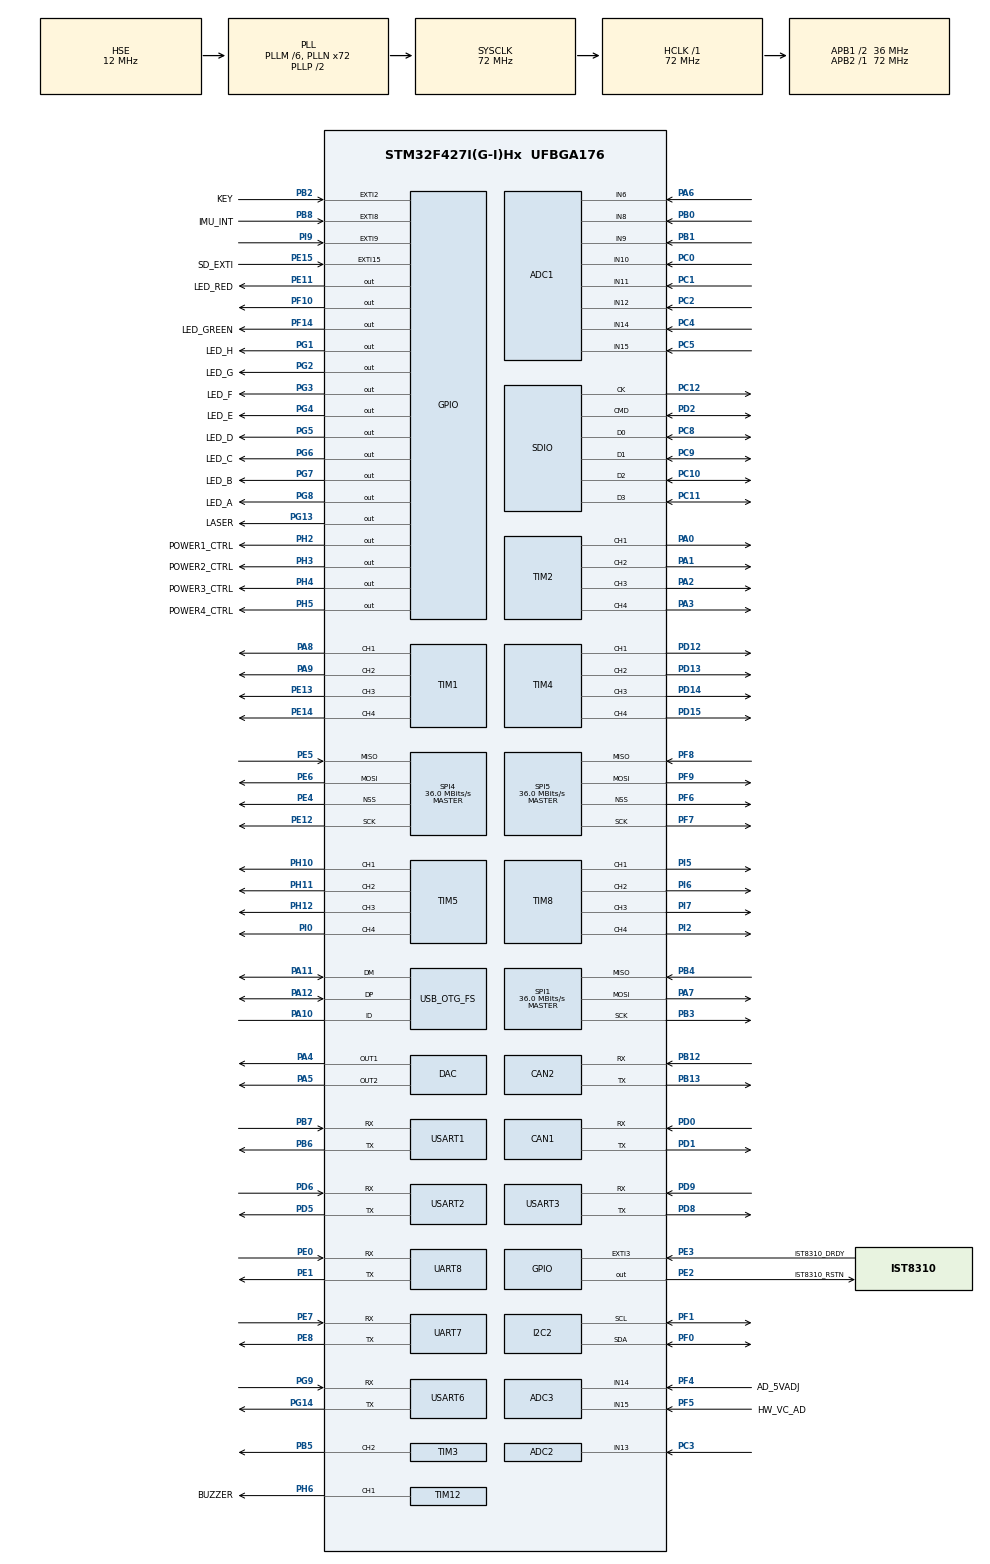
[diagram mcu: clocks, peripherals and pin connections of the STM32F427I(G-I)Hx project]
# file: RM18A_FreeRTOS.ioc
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ADC1.Channel-0\#ChannelRegularConversion=ADC_CHANNEL_6
ADC1.NbrOfConversionFlag=1
ADC1.Rank-0\#ChannelRegularConversion=1
ADC1.SamplingTime-0\#ChannelRegularConversion=ADC_SAMPLETIME_3CYCLES
ADC1.master=1
ADC2.Channel-0\#ChannelRegularConversion=ADC_CHANNEL_13
ADC2.NbrOfConversionFlag=1
ADC2.Rank-0\#ChannelRegularConversion=1
ADC2.SamplingTime-0\#ChannelRegularConversion=ADC_SAMPLETIME_3CYCLES
ADC3.Channel-0\#ChannelRegularConversion=ADC_CHANNEL_14
ADC3.NbrOfConversionFlag=1
ADC3.Rank-0\#ChannelRegularConversion=1
ADC3.SamplingTime-0\#ChannelRegularConversion=ADC_SAMPLETIME_3CYCLES
CAN1.CalculateTimeQuantum=444.44444444444446
CAN2.CalculateTimeQuantum=444.44444444444446
FREERTOS.Tasks01=defaultTask,0,128,StartDefaultTask,Default,NULL
Mcu.Family=STM32F4
Mcu.Name=STM32F427I(G-I)Hx
Mcu.Package=UFBGA176
NVIC.PriorityGroup=NVIC_PRIORITYGROUP_4
NVIC.TIM8_TRG_COM_TIM14_IRQn=true\:5\:0\:false\:false\:true\:true\:false\:true
NVIC.TimeBase=TIM8_TRG_COM_TIM14_IRQn
NVIC.TimeBaseIP=TIM14
PA0/WKUP.Signal=S_TIM2_CH1_ETR
PA1.Signal=S_TIM2_CH2
PA10.Mode=OTG/Dual_Role_Device
PA10.Signal=USB_OTG_FS_ID
PA11.Mode=OTG/Dual_Role_Device
PA11.Signal=USB_OTG_FS_DM
PA12.Mode=OTG/Dual_Role_Device
PA12.Signal=USB_OTG_FS_DP
PA13.Mode=Serial_Wire
PA13.Signal=SYS_JTMS-SWDIO
PA14.Mode=Serial_Wire
PA14.Signal=SYS_JTCK-SWCLK
PA2.Signal=S_TIM2_CH3
PA3.Signal=S_TIM2_CH4
PA4.Signal=COMP_DAC1_group
PA5.Signal=COMP_DAC2_group
PA6.Signal=ADCx_IN6
PA7.Mode=Full_Duplex_Master
PA7.Signal=SPI1_MOSI
PA8.Signal=S_TIM1_CH1
PA9.Signal=S_TIM1_CH2
PB0.Signal=ADCx_IN8
PB1.Signal=ADCx_IN9
PB12.Mode=Slave
PB12.Signal=CAN2_RX
PB13.Mode=Slave
PB13.Signal=CAN2_TX
PB2/BOOT1.GPIO_Label=KEY
PB2/BOOT1.Signal=GPXTI2
PB3.Mode=Full_Duplex_Master
PB3.Signal=SPI1_SCK
PB4.Mode=Full_Duplex_Master
PB4.Signal=SPI1_MISO
PB5.Signal=S_TIM3_CH2
PB6.Mode=Asynchronous
PB6.Signal=USART1_TX
PB7.Mode=Asynchronous
PB7.Signal=USART1_RX
PB8.GPIO_Label=IMU_INT
PB8.Signal=GPXTI8
PC0.Signal=ADCx_IN10
PC1.Signal=ADCx_IN11
PC10.Mode=SD_4_bits_Wide_bus
PC10.Signal=SDIO_D2
PC11.Mode=SD_4_bits_Wide_bus
PC11.Signal=SDIO_D3
PC12.Mode=SD_4_bits_Wide_bus
PC12.Signal=SDIO_CK
PC2.Signal=ADCx_IN12
PC3.Signal=ADCx_IN13
PC4.Signal=ADCx_IN14
PC5.Signal=ADCx_IN15
PC8.Mode=SD_4_bits_Wide_bus
PC8.Signal=SDIO_D0
PC9.Mode=SD_4_bits_Wide_bus
PC9.Signal=SDIO_D1
PD0.Mode=Master
PD0.Signal=CAN1_RX
PD1.Mode=Master
PD1.Signal=CAN1_TX
PD12.Signal=S_TIM4_CH1
PD13.Signal=S_TIM4_CH2
PD14.Signal=S_TIM4_CH3
PD15.Signal=S_TIM4_CH4
PD2.Mode=SD_4_bits_Wide_bus
PD2.Signal=SDIO_CMD
PD5.Mode=Asynchronous
PD5.Signal=USART2_TX
PD6.Mode=Asynchronous
PD6.Signal=USART2_RX
PD8.Mode=Asynchronous
PD8.Signal=USART3_TX
PD9.Mode=Asynchronous
PD9.Signal=USART3_RX
PE0.Mode=Asynchronous
PE0.Signal=UART8_RX
PE1.Mode=Asynchronous
PE1.Signal=UART8_TX
PE11.GPIO_Label=LED_RED
PE11.Signal=GPIO_Output
PE12.Mode=Full_Duplex_Master
PE12.Signal=SPI4_SCK
PE13.Signal=S_TIM1_CH3
PE14.Signal=S_TIM1_CH4
PE15.GPIO_Label=SD_EXTI
PE15.Signal=GPXTI15
PE2.GPIO_Label=IST8310_RSTN
PE2.Signal=GPIO_Output
PE3.GPIO_Label=IST8310_DRDY
PE3.Signal=GPXTI3
PE4.Mode=NSS_Signal_Hard_Output
PE4.Signal=SPI4_NSS
PE5.Mode=Full_Duplex_Master
PE5.Signal=SPI4_MISO
PE6.Mode=Full_Duplex_Master
PE6.Signal=SPI4_MOSI
PE7.Mode=Asynchronous
PE7.Signal=UART7_RX
PE8.Mode=Asynchronous
PE8.Signal=UART7_TX
PF0.Mode=I2C
PF0.Signal=I2C2_SDA
PF1.Mode=I2C
PF1.Signal=I2C2_SCL
PF10.Signal=GPIO_Output
PF14.GPIO_Label=LED_GREEN
PF14.Signal=GPIO_Output
PF4.GPIO_Label=AD_5VADJ
PF4.Mode=IN14
PF4.Signal=ADC3_IN14
PF5.GPIO_Label=HW_VC_AD
PF5.Mode=IN15
PF5.Signal=ADC3_IN15
PF6.Mode=NSS_Signal_Hard_Output
PF6.Signal=SPI5_NSS
PF7.Mode=Full_Duplex_Master
PF7.Signal=SPI5_SCK
PF8.Mode=Full_Duplex_Master
PF8.Signal=SPI5_MISO
PF9.Mode=Full_Duplex_Master
PF9.Signal=SPI5_MOSI
PG1.GPIO_Label=LED_H
PG1.Signal=GPIO_Output
PG13.GPIO_Label=LASER
PG13.Signal=GPIO_Output
PG14.Mode=Asynchronous
PG14.Signal=USART6_TX
PG2.GPIO_Label=LED_G
PG2.Signal=GPIO_Output
PG3.GPIO_Label=LED_F
PG3.Signal=GPIO_Output
PG4.GPIO_Label=LED_E
PG4.Signal=GPIO_Output
PG5.GPIO_Label=LED_D
PG5.Signal=GPIO_Output
PG6.GPIO_Label=LED_C
PG6.Signal=GPIO_Output
PG7.GPIO_Label=LED_B
PG7.Signal=GPIO_Output
PG8.GPIO_Label=LED_A
PG8.Signal=GPIO_Output
PG9.Mode=Asynchronous
PG9.Signal=USART6_RX
PH0/OSC_IN.Mode=HSE-External-Oscillator
PH0/OSC_IN.Signal=RCC_OSC_IN
PH1/OSC_OUT.Mode=HSE-External-Oscillator
PH1/OSC_OUT.Signal=RCC_OSC_OUT
PH10.Signal=S_TIM5_CH1
PH11.Signal=S_TIM5_CH2
PH12.Signal=S_TIM5_CH3
PH2.GPIO_Label=POWER1_CTRL
PH2.Signal=GPIO_Output
PH3.GPIO_Label=POWER2_CTRL
PH3.Signal=GPIO_Output
PH4.GPIO_Label=POWER3_CTRL
PH4.Signal=GPIO_Output
PH5.GPIO_Label=POWER4_CTRL
PH5.Signal=GPIO_Output
PH6.GPIO_Label=BUZZER
PH6.Signal=S_TIM12_CH1
PI0.Signal=S_TIM5_CH4
PI2.Signal=S_TIM8_CH4
PI5.Signal=S_TIM8_CH1
PI6.Signal=S_TIM8_CH2
PI7.Signal=S_TIM8_CH3
PI9.Signal=GPXTI9
ProjectManager.HeapSize=0x200
ProjectManager.StackSize=0x400
ProjectManager.TargetToolchain=Makefile
RCC.48MHZClocksFreq_Value=48000000
RCC.AHBFreq_Value=72000000
RCC.APB1CLKDivider=RCC_HCLK_DIV2
RCC.APB1Freq_Value=36000000
RCC.APB1TimFreq_Value=72000000
RCC.APB2Freq_Value=72000000
RCC.APB2TimFreq_Value=72000000
RCC.CortexFreq_Value=72000000
RCC.HCLKFreq_Value=72000000
RCC.HSE_VALUE=12000000
RCC.HSI_VALUE=16000000
RCC.LSE_VALUE=32768
RCC.PLLM=6
RCC.PLLN=72
RCC.PLLQ=3
RCC.SYSCLKFreq_VALUE=72000000
RCC.SYSCLKSource=RCC_SYSCLKSOURCE_PLLCLK
RCC.VCOOutputFreq_Value=144000000
SH.ADCx_IN10.0=ADC1_IN10,IN10
SH.ADCx_IN11.0=ADC1_IN11,IN11
SH.ADCx_IN12.0=ADC1_IN12,IN12
SH.ADCx_IN13.0=ADC2_IN13,IN13
SH.ADCx_IN13.1=ADC1_IN13,IN13
SH.ADCx_IN14.0=ADC1_IN14,IN14
SH.ADCx_IN15.0=ADC1_IN15,IN15
SH.ADCx_IN6.0=ADC1_IN6,IN6
SH.ADCx_IN8.0=ADC1_IN8,IN8
SH.ADCx_IN9.0=ADC1_IN9,IN9
SH.COMP_DAC1_group.0=DAC_OUT1,DAC_OUT1
SH.COMP_DAC2_group.0=DAC_OUT2,DAC_OUT2
SH.S_TIM12_CH1.0=TIM12_CH1,Output Compare1 CH1
SH.S_TIM1_CH1.0=TIM1_CH1,PWM Generation1 CH1
SH.S_TIM1_CH2.0=TIM1_CH2,Output Compare2 CH2
SH.S_TIM1_CH3.0=TIM1_CH3,PWM Generation3 CH3
SH.S_TIM1_CH4.0=TIM1_CH4,PWM Generation4 CH4
SH.S_TIM2_CH1_ETR.0=TIM2_CH1,PWM Generation1 CH1
SH.S_TIM2_CH2.0=TIM2_CH2,PWM Generation2 CH2
SH.S_TIM2_CH3.0=TIM2_CH3,PWM Generation3 CH3
SH.S_TIM2_CH4.0=TIM2_CH4,PWM Generation4 CH4
SH.S_TIM3_CH2.0=TIM3_CH2,PWM Generation2 CH2
SH.S_TIM4_CH1.0=TIM4_CH1,PWM Generation1 CH1
SH.S_TIM4_CH2.0=TIM4_CH2,PWM Generation2 CH2
SH.S_TIM4_CH3.0=TIM4_CH3,PWM Generation3 CH3
SH.S_TIM4_CH4.0=TIM4_CH4,PWM Generation4 CH4
SH.S_TIM5_CH1.0=TIM5_CH1,PWM Generation1 CH1
SH.S_TIM5_CH2.0=TIM5_CH2,PWM Generation2 CH2
SH.S_TIM5_CH3.0=TIM5_CH3,PWM Generation3 CH3
SH.S_TIM5_CH4.0=TIM5_CH4,PWM Generation4 CH4
SH.S_TIM8_CH1.0=TIM8_CH1,PWM Generation1 CH1
SH.S_TIM8_CH2.0=TIM8_CH2,PWM Generation2 CH2
SH.S_TIM8_CH3.0=TIM8_CH3,PWM Generation3 CH3
SH.S_TIM8_CH4.0=TIM8_CH4,PWM Generation4 CH4
SPI1.CalculateBaudRate=36.0 MBits/s
SPI1.Direction=SPI_DIRECTION_2LINES
SPI1.Mode=SPI_MODE_MASTER
SPI1.VirtualType=VM_MASTER
SPI4.CalculateBaudRate=36.0 MBits/s
SPI4.Direction=SPI_DIRECTION_2LINES
SPI4.Mode=SPI_MODE_MASTER
SPI4.VirtualNSS=VM_NSSHARD
SPI4.VirtualType=VM_MASTER
SPI5.CalculateBaudRate=36.0 MBits/s
SPI5.Direction=SPI_DIRECTION_2LINES
SPI5.Mode=SPI_MODE_MASTER
SPI5.VirtualNSS=VM_NSSHARD
SPI5.VirtualType=VM_MASTER
TIM1.Channel-Output\ Compare2\ CH2=TIM_CHANNEL_2
TIM1.Channel-PWM\ Generation1\ CH1=TIM_CHANNEL_1
TIM1.Channel-PWM\ Generation3\ CH3=TIM_CHANNEL_3
TIM1.Channel-PWM\ Generation4\ CH4=TIM_CHANNEL_4
TIM12.Channel-Output\ Compare1\ CH1=TIM_CHANNEL_1
TIM2.Channel-PWM\ Generation1\ CH1=TIM_CHANNEL_1
TIM2.Channel-PWM\ Generation2\ CH2=TIM_CHANNEL_2
TIM2.Channel-PWM\ Generation3\ CH3=TIM_CHANNEL_3
TIM2.Channel-PWM\ Generation4\ CH4=TIM_CHANNEL_4
TIM3.Channel-PWM\ Generation2\ CH2=TIM_CHANNEL_2
TIM4.Channel-PWM\ Generation1\ CH1=TIM_CHANNEL_1
TIM4.Channel-PWM\ Generation2\ CH2=TIM_CHANNEL_2
TIM4.Channel-PWM\ Generation3\ CH3=TIM_CHANNEL_3
TIM4.Channel-PWM\ Generation4\ CH4=TIM_CHANNEL_4
TIM5.Channel-PWM\ Generation1\ CH1=TIM_CHANNEL_1
TIM5.Channel-PWM\ Generation2\ CH2=TIM_CHANNEL_2
TIM5.Channel-PWM\ Generation3\ CH3=TIM_CHANNEL_3
TIM5.Channel-PWM\ Generation4\ CH4=TIM_CHANNEL_4
TIM8.Channel-PWM\ Generation1\ CH1=TIM_CHANNEL_1
TIM8.Channel-PWM\ Generation2\ CH2=TIM_CHANNEL_2
TIM8.Channel-PWM\ Generation3\ CH3=TIM_CHANNEL_3
TIM8.Channel-PWM\ Generation4\ CH4=TIM_CHANNEL_4
UART7.VirtualMode=Asynchronous
UART8.VirtualMode=Asynchronous
USART1.VirtualMode=VM_ASYNC
USART2.VirtualMode=VM_ASYNC
USART3.VirtualMode=VM_ASYNC
USART6.VirtualMode=VM_ASYNC
VP_CRC_VS_CRC.Mode=CRC_Activate
VP_FREERTOS_VS_CMSIS_V1.Mode=CMSIS_V1
VP_SYS_VS_tim14.Mode=TIM14
board=custom

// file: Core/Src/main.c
/* USER CODE BEGIN Header */
/**
  ******************************************************************************
  * @file           : main.c
  * @brief          : Main program body
  ******************************************************************************
  * @attention
  *
  * <h2><center>&copy; Copyright (c) 2019 STMicroelectronics.
  * All rights reserved.</center></h2>
  *
  * This software component is licensed by ST under Ultimate Liberty license
  * SLA0044, the "License"; You may not use this file except in compliance with
  * the License. You may obtain a copy of the License at:
  *                             www.st.com/SLA0044
  *
  ******************************************************************************
  */
/* USER CODE END Header */

#include "main.h"
#include "cmsis_os.h"

ADC_HandleTypeDef hadc1;
ADC_HandleTypeDef hadc2;
ADC_HandleTypeDef hadc3;

CAN_HandleTypeDef hcan1;
CAN_HandleTypeDef hcan2;

CRC_HandleTypeDef hcrc;

DAC_HandleTypeDef hdac;

I2C_HandleTypeDef hi2c2;

SD_HandleTypeDef hsd;

SPI_HandleTypeDef hspi1;
SPI_HandleTypeDef hspi4;
SPI_HandleTypeDef hspi5;

TIM_HandleTypeDef htim1;
TIM_HandleTypeDef htim2;
TIM_HandleTypeDef htim3;
TIM_HandleTypeDef htim4;
TIM_HandleTypeDef htim5;
TIM_HandleTypeDef htim8;
TIM_HandleTypeDef htim12;

UART_HandleTypeDef huart7;
UART_HandleTypeDef huart8;
UART_HandleTypeDef huart1;
UART_HandleTypeDef huart2;
UART_HandleTypeDef huart3;
UART_HandleTypeDef huart6;

osThreadId defaultTaskHandle;

void SystemClock_Config(void);
static void MX_GPIO_Init(void);
static void MX_CRC_Init(void);
static void MX_USB_OTG_FS_USB_Init(void);
static void MX_SDIO_SD_Init(void);
static void MX_CAN1_Init(void);
static void MX_CAN2_Init(void);
static void MX_I2C2_Init(void);
static void MX_ADC1_Init(void);
static void MX_ADC2_Init(void);
static void MX_DAC_Init(void);
static void MX_SPI1_Init(void);
static void MX_TIM1_Init(void);
static void MX_TIM2_Init(void);
static void MX_TIM3_Init(void);
static void MX_TIM4_Init(void);
static void MX_TIM5_Init(void);
static void MX_TIM12_Init(void);
static void MX_UART8_Init(void);
static void MX_USART1_UART_Init(void);
static void MX_USART2_UART_Init(void);
static void MX_USART3_UART_Init(void);
static void MX_USART6_UART_Init(void);
static void MX_ADC3_Init(void);
static void MX_SPI4_Init(void);
static void MX_SPI5_Init(void);
static void MX_TIM8_Init(void);
static void MX_UART7_Init(void);
void StartDefaultTask(void const *argument);

int main(void)
{

  /* MCU Configuration--------------------------------------------------------*/

  /* Reset of all peripherals, Initializes the Flash interface and the Systick. */
  HAL_Init();

  /* Configure the system clock */
  SystemClock_Config();

  /* Initialize all configured peripherals */
  MX_GPIO_Init();
  MX_CRC_Init();
  MX_USB_OTG_FS_USB_Init();
  MX_SDIO_SD_Init();
  MX_CAN1_Init();
  MX_CAN2_Init();
  MX_I2C2_Init();
  MX_ADC1_Init();
  MX_ADC2_Init();
  MX_DAC_Init();
  MX_SPI1_Init();
  MX_TIM1_Init();
  MX_TIM2_Init();
  MX_TIM3_Init();
  MX_TIM4_Init();
  MX_TIM5_Init();
  MX_TIM12_Init();
  MX_UART8_Init();
  MX_USART1_UART_Init();
  MX_USART2_UART_Init();
  MX_USART3_UART_Init();
  MX_USART6_UART_Init();
  MX_ADC3_Init();
  MX_SPI4_Init();
  MX_SPI5_Init();
  MX_TIM8_Init();
  MX_UART7_Init();

  /* Create the thread(s) */
  /* definition and creation of defaultTask */
  osThreadDef(defaultTask, StartDefaultTask, osPriorityNormal, 0, 128);
  defaultTaskHandle = osThreadCreate(osThread(defaultTask), NULL);

  /* Start scheduler */
  osKernelStart();

  /* We should never get here as control is now taken by the scheduler */

  /* Infinite loop */
  while (1)
  {

  }
}

void SystemClock_Config(void)
{
  RCC_OscInitTypeDef RCC_OscInitStruct = {0};
  RCC_ClkInitTypeDef RCC_ClkInitStruct = {0};

  /** Configure the main internal regulator output voltage
  */
  __HAL_RCC_PWR_CLK_ENABLE();
  __HAL_PWR_VOLTAGESCALING_CONFIG(PWR_REGULATOR_VOLTAGE_SCALE3);
  /** Initializes the CPU, AHB and APB busses clocks
  */
  RCC_OscInitStruct.OscillatorType = RCC_OSCILLATORTYPE_HSE;
  RCC_OscInitStruct.HSEState = RCC_HSE_ON;
  RCC_OscInitStruct.PLL.PLLState = RCC_PLL_ON;
  RCC_OscInitStruct.PLL.PLLSource = RCC_PLLSOURCE_HSE;
  RCC_OscInitStruct.PLL.PLLM = 6;
  RCC_OscInitStruct.PLL.PLLN = 72;
  RCC_OscInitStruct.PLL.PLLP = RCC_PLLP_DIV2;
  RCC_OscInitStruct.PLL.PLLQ = 3;
  if (HAL_RCC_OscConfig(&RCC_OscInitStruct) != HAL_OK)
  {
    Error_Handler();
  }
  /** Initializes the CPU, AHB and APB busses clocks
  */
  RCC_ClkInitStruct.ClockType = RCC_CLOCKTYPE_HCLK | RCC_CLOCKTYPE_SYSCLK | RCC_CLOCKTYPE_PCLK1 | RCC_CLOCKTYPE_PCLK2;
  RCC_ClkInitStruct.SYSCLKSource = RCC_SYSCLKSOURCE_PLLCLK;
  RCC_ClkInitStruct.AHBCLKDivider = RCC_SYSCLK_DIV1;
  RCC_ClkInitStruct.APB1CLKDivider = RCC_HCLK_DIV2;
  RCC_ClkInitStruct.APB2CLKDivider = RCC_HCLK_DIV1;

  if (HAL_RCC_ClockConfig(&RCC_ClkInitStruct, FLASH_LATENCY_2) != HAL_OK)
  {
    Error_Handler();
  }
}

static void MX_ADC1_Init(void)
{

  ADC_ChannelConfTypeDef sConfig = {0};

  /** Configure the global features of the ADC (Clock, Resolution, Data Alignment and number of conversion)
  */
  hadc1.Instance = ADC1;
  hadc1.Init.ClockPrescaler = ADC_CLOCK_SYNC_PCLK_DIV2;
  hadc1.Init.Resolution = ADC_RESOLUTION_12B;
  hadc1.Init.ScanConvMode = DISABLE;
  hadc1.Init.ContinuousConvMode = DISABLE;
  hadc1.Init.DiscontinuousConvMode = DISABLE;
  hadc1.Init.ExternalTrigConvEdge = ADC_EXTERNALTRIGCONVEDGE_NONE;
  hadc1.Init.ExternalTrigConv = ADC_SOFTWARE_START;
  hadc1.Init.DataAlign = ADC_DATAALIGN_RIGHT;
  hadc1.Init.NbrOfConversion = 1;
  hadc1.Init.DMAContinuousRequests = DISABLE;
  hadc1.Init.EOCSelection = ADC_EOC_SINGLE_CONV;
  if (HAL_ADC_Init(&hadc1) != HAL_OK)
  {
    Error_Handler();
  }
  /** Configure for the selected ADC regular channel its corresponding rank in the sequencer and its sample time.
  */
  sConfig.Channel = ADC_CHANNEL_6;
  sConfig.Rank = 1;
  sConfig.SamplingTime = ADC_SAMPLETIME_3CYCLES;
  if (HAL_ADC_ConfigChannel(&hadc1, &sConfig) != HAL_OK)
  {
    Error_Handler();
  }
}

static void MX_ADC2_Init(void)
{

  ADC_ChannelConfTypeDef sConfig = {0};

  /** Configure the global features of the ADC (Clock, Resolution, Data Alignment and number of conversion)
  */
  hadc2.Instance = ADC2;
  hadc2.Init.ClockPrescaler = ADC_CLOCK_SYNC_PCLK_DIV2;
  hadc2.Init.Resolution = ADC_RESOLUTION_12B;
  hadc2.Init.ScanConvMode = DISABLE;
  hadc2.Init.ContinuousConvMode = DISABLE;
  hadc2.Init.DiscontinuousConvMode = DISABLE;
  hadc2.Init.ExternalTrigConvEdge = ADC_EXTERNALTRIGCONVEDGE_NONE;
  hadc2.Init.ExternalTrigConv = ADC_SOFTWARE_START;
  hadc2.Init.DataAlign = ADC_DATAALIGN_RIGHT;
  hadc2.Init.NbrOfConversion = 1;
  hadc2.Init.DMAContinuousRequests = DISABLE;
  hadc2.Init.EOCSelection = ADC_EOC_SINGLE_CONV;
  if (HAL_ADC_Init(&hadc2) != HAL_OK)
  {
    Error_Handler();
  }
  /** Configure for the selected ADC regular channel its corresponding rank in the sequencer and its sample time.
  */
  sConfig.Channel = ADC_CHANNEL_13;
  sConfig.Rank = 1;
  sConfig.SamplingTime = ADC_SAMPLETIME_3CYCLES;
  if (HAL_ADC_ConfigChannel(&hadc2, &sConfig) != HAL_OK)
  {
    Error_Handler();
  }
}

static void MX_ADC3_Init(void)
{

  ADC_ChannelConfTypeDef sConfig = {0};

  /** Configure the global features of the ADC (Clock, Resolution, Data Alignment and number of conversion)
  */
  hadc3.Instance = ADC3;
  hadc3.Init.ClockPrescaler = ADC_CLOCK_SYNC_PCLK_DIV2;
  hadc3.Init.Resolution = ADC_RESOLUTION_12B;
  hadc3.Init.ScanConvMode = DISABLE;
  hadc3.Init.ContinuousConvMode = DISABLE;
  hadc3.Init.DiscontinuousConvMode = DISABLE;
  hadc3.Init.ExternalTrigConvEdge = ADC_EXTERNALTRIGCONVEDGE_NONE;
  hadc3.Init.ExternalTrigConv = ADC_SOFTWARE_START;
  hadc3.Init.DataAlign = ADC_DATAALIGN_RIGHT;
  hadc3.Init.NbrOfConversion = 1;
  hadc3.Init.DMAContinuousRequests = DISABLE;
  hadc3.Init.EOCSelection = ADC_EOC_SINGLE_CONV;
  if (HAL_ADC_Init(&hadc3) != HAL_OK)
  {
    Error_Handler();
  }
  /** Configure for the selected ADC regular channel its corresponding rank in the sequencer and its sample time.
  */
  sConfig.Channel = ADC_CHANNEL_14;
  sConfig.Rank = 1;
  sConfig.SamplingTime = ADC_SAMPLETIME_3CYCLES;
  if (HAL_ADC_ConfigChannel(&hadc3, &sConfig) != HAL_OK)
  {
    Error_Handler();
  }
}

static void MX_CAN1_Init(void)
{

  hcan1.Instance = CAN1;
  hcan1.Init.Prescaler = 16;
  hcan1.Init.Mode = CAN_MODE_NORMAL;
  hcan1.Init.SyncJumpWidth = CAN_SJW_1TQ;
  hcan1.Init.TimeSeg1 = CAN_BS1_1TQ;
  hcan1.Init.TimeSeg2 = CAN_BS2_1TQ;
  hcan1.Init.TimeTriggeredMode = DISABLE;
  hcan1.Init.AutoBusOff = DISABLE;
  hcan1.Init.AutoWakeUp = DISABLE;
  hcan1.Init.AutoRetransmission = DISABLE;
  hcan1.Init.ReceiveFifoLocked = DISABLE;
  hcan1.Init.TransmitFifoPriority = DISABLE;
  if (HAL_CAN_Init(&hcan1) != HAL_OK)
  {
    Error_Handler();
  }
}

static void MX_CAN2_Init(void)
{

  hcan2.Instance = CAN2;
  hcan2.Init.Prescaler = 16;
  hcan2.Init.Mode = CAN_MODE_NORMAL;
  hcan2.Init.SyncJumpWidth = CAN_SJW_1TQ;
  hcan2.Init.TimeSeg1 = CAN_BS1_1TQ;
  hcan2.Init.TimeSeg2 = CAN_BS2_1TQ;
  hcan2.Init.TimeTriggeredMode = DISABLE;
  hcan2.Init.AutoBusOff = DISABLE;
  hcan2.Init.AutoWakeUp = DISABLE;
  hcan2.Init.AutoRetransmission = DISABLE;
  hcan2.Init.ReceiveFifoLocked = DISABLE;
  hcan2.Init.TransmitFifoPriority = DISABLE;
  if (HAL_CAN_Init(&hcan2) != HAL_OK)
  {
    Error_Handler();
  }
}

static void MX_CRC_Init(void)
{

  hcrc.Instance = CRC;
  if (HAL_CRC_Init(&hcrc) != HAL_OK)
  {
    Error_Handler();
  }
}

static void MX_DAC_Init(void)
{

  DAC_ChannelConfTypeDef sConfig = {0};

  /** DAC Initialization
  */
  hdac.Instance = DAC;
  if (HAL_DAC_Init(&hdac) != HAL_OK)
  {
    Error_Handler();
  }
  /** DAC channel OUT1 config
  */
  sConfig.DAC_Trigger = DAC_TRIGGER_NONE;
  sConfig.DAC_OutputBuffer = DAC_OUTPUTBUFFER_ENABLE;
  if (HAL_DAC_ConfigChannel(&hdac, &sConfig, DAC_CHANNEL_1) != HAL_OK)
  {
    Error_Handler();
  }
  /** DAC channel OUT2 config
  */
  if (HAL_DAC_ConfigChannel(&hdac, &sConfig, DAC_CHANNEL_2) != HAL_OK)
  {
    Error_Handler();
  }
}

static void MX_I2C2_Init(void)
{

  hi2c2.Instance = I2C2;
  hi2c2.Init.ClockSpeed = 100000;
  hi2c2.Init.DutyCycle = I2C_DUTYCYCLE_2;
  hi2c2.Init.OwnAddress1 = 0;
  hi2c2.Init.AddressingMode = I2C_ADDRESSINGMODE_7BIT;
  hi2c2.Init.DualAddressMode = I2C_DUALADDRESS_DISABLE;
  hi2c2.Init.OwnAddress2 = 0;
  hi2c2.Init.GeneralCallMode = I2C_GENERALCALL_DISABLE;
  hi2c2.Init.NoStretchMode = I2C_NOSTRETCH_DISABLE;
  if (HAL_I2C_Init(&hi2c2) != HAL_OK)
  {
    Error_Handler();
  }
  /** Configure Analogue filter
  */
  if (HAL_I2CEx_ConfigAnalogFilter(&hi2c2, I2C_ANALOGFILTER_ENABLE) != HAL_OK)
  {
    Error_Handler();
  }
  /** Configure Digital filter
  */
  if (HAL_I2CEx_ConfigDigitalFilter(&hi2c2, 0) != HAL_OK)
  {
    Error_Handler();
  }
}

static void MX_SDIO_SD_Init(void)
{

  hsd.Instance = SDIO;
  hsd.Init.ClockEdge = SDIO_CLOCK_EDGE_RISING;
  hsd.Init.ClockBypass = SDIO_CLOCK_BYPASS_DISABLE;
  hsd.Init.ClockPowerSave = SDIO_CLOCK_POWER_SAVE_DISABLE;
  hsd.Init.BusWide = SDIO_BUS_WIDE_1B;
  hsd.Init.HardwareFlowControl = SDIO_HARDWARE_FLOW_CONTROL_DISABLE;
  hsd.Init.ClockDiv = 0;
  if (HAL_SD_Init(&hsd) != HAL_OK)
  {
    Error_Handler();
  }
  if (HAL_SD_ConfigWideBusOperation(&hsd, SDIO_BUS_WIDE_4B) != HAL_OK)
  {
    Error_Handler();
  }
}

static void MX_SPI1_Init(void)
{

  /* SPI1 parameter configuration*/
  hspi1.Instance = SPI1;
  hspi1.Init.Mode = SPI_MODE_MASTER;
  hspi1.Init.Direction = SPI_DIRECTION_2LINES;
  hspi1.Init.DataSize = SPI_DATASIZE_8BIT;
  hspi1.Init.CLKPolarity = SPI_POLARITY_LOW;
  hspi1.Init.CLKPhase = SPI_PHASE_1EDGE;
  hspi1.Init.NSS = SPI_NSS_SOFT;
  hspi1.Init.BaudRatePrescaler = SPI_BAUDRATEPRESCALER_2;
  hspi1.Init.FirstBit = SPI_FIRSTBIT_MSB;
  hspi1.Init.TIMode = SPI_TIMODE_DISABLE;
  hspi1.Init.CRCCalculation = SPI_CRCCALCULATION_DISABLE;
  hspi1.Init.CRCPolynomial = 10;
  if (HAL_SPI_Init(&hspi1) != HAL_OK)
  {
    Error_Handler();
  }
}

static void MX_SPI4_Init(void)
{

  /* SPI4 parameter configuration*/
  hspi4.Instance = SPI4;
  hspi4.Init.Mode = SPI_MODE_MASTER;
  hspi4.Init.Direction = SPI_DIRECTION_2LINES;
  hspi4.Init.DataSize = SPI_DATASIZE_8BIT;
  hspi4.Init.CLKPolarity = SPI_POLARITY_LOW;
  hspi4.Init.CLKPhase = SPI_PHASE_1EDGE;
  hspi4.Init.NSS = SPI_NSS_HARD_OUTPUT;
  hspi4.Init.BaudRatePrescaler = SPI_BAUDRATEPRESCALER_2;
  hspi4.Init.FirstBit = SPI_FIRSTBIT_MSB;
  hspi4.Init.TIMode = SPI_TIMODE_DISABLE;
  hspi4.Init.CRCCalculation = SPI_CRCCALCULATION_DISABLE;
  hspi4.Init.CRCPolynomial = 10;
  if (HAL_SPI_Init(&hspi4) != HAL_OK)
  {
    Error_Handler();
  }
}

static void MX_SPI5_Init(void)
{

  /* SPI5 parameter configuration*/
  hspi5.Instance = SPI5;
  hspi5.Init.Mode = SPI_MODE_MASTER;
  hspi5.Init.Direction = SPI_DIRECTION_2LINES;
  hspi5.Init.DataSize = SPI_DATASIZE_8BIT;
  hspi5.Init.CLKPolarity = SPI_POLARITY_LOW;
  hspi5.Init.CLKPhase = SPI_PHASE_1EDGE;
  hspi5.Init.NSS = SPI_NSS_HARD_OUTPUT;
  hspi5.Init.BaudRatePrescaler = SPI_BAUDRATEPRESCALER_2;
  hspi5.Init.FirstBit = SPI_FIRSTBIT_MSB;
  hspi5.Init.TIMode = SPI_TIMODE_DISABLE;
  hspi5.Init.CRCCalculation = SPI_CRCCALCULATION_DISABLE;
  hspi5.Init.CRCPolynomial = 10;
  if (HAL_SPI_Init(&hspi5) != HAL_OK)
  {
    Error_Handler();
  }
}

static void MX_TIM1_Init(void)
{

  TIM_MasterConfigTypeDef sMasterConfig = {0};
  TIM_OC_InitTypeDef sConfigOC = {0};
  TIM_BreakDeadTimeConfigTypeDef sBreakDeadTimeConfig = {0};

  htim1.Instance = TIM1;
  htim1.Init.Prescaler = 0;
  htim1.Init.CounterMode = TIM_COUNTERMODE_UP;
  htim1.Init.Period = 0;
  htim1.Init.ClockDivision = TIM_CLOCKDIVISION_DIV1;
  htim1.Init.RepetitionCounter = 0;
  htim1.Init.AutoReloadPreload = TIM_AUTORELOAD_PRELOAD_DISABLE;
  if (HAL_TIM_PWM_Init(&htim1) != HAL_OK)
  {
    Error_Handler();
  }
  if (HAL_TIM_OC_Init(&htim1) != HAL_OK)
  {
    Error_Handler();
  }
  sMasterConfig.MasterOutputTrigger = TIM_TRGO_RESET;
  sMasterConfig.MasterSlaveMode = TIM_MASTERSLAVEMODE_DISABLE;
  if (HAL_TIMEx_MasterConfigSynchronization(&htim1, &sMasterConfig) != HAL_OK)
  {
    Error_Handler();
  }
  sConfigOC.OCMode = TIM_OCMODE_PWM1;
  sConfigOC.Pulse = 0;
  sConfigOC.OCPolarity = TIM_OCPOLARITY_HIGH;
  sConfigOC.OCNPolarity = TIM_OCNPOLARITY_HIGH;
  sConfigOC.OCFastMode = TIM_OCFAST_DISABLE;
  sConfigOC.OCIdleState = TIM_OCIDLESTATE_RESET;
  sConfigOC.OCNIdleState = TIM_OCNIDLESTATE_RESET;
  if (HAL_TIM_PWM_ConfigChannel(&htim1, &sConfigOC, TIM_CHANNEL_1) != HAL_OK)
  {
    Error_Handler();
  }
  sConfigOC.OCMode = TIM_OCMODE_TIMING;
  if (HAL_TIM_OC_ConfigChannel(&htim1, &sConfigOC, TIM_CHANNEL_2) != HAL_OK)
  {
    Error_Handler();
  }
  sConfigOC.OCMode = TIM_OCMODE_PWM1;
  if (HAL_TIM_PWM_ConfigChannel(&htim1, &sConfigOC, TIM_CHANNEL_3) != HAL_OK)
  {
    Error_Handler();
  }
  if (HAL_TIM_PWM_ConfigChannel(&htim1, &sConfigOC, TIM_CHANNEL_4) != HAL_OK)
  {
    Error_Handler();
  }
  sBreakDeadTimeConfig.OffStateRunMode = TIM_OSSR_DISABLE;
  sBreakDeadTimeConfig.OffStateIDLEMode = TIM_OSSI_DISABLE;
  sBreakDeadTimeConfig.LockLevel = TIM_LOCKLEVEL_OFF;
  sBreakDeadTimeConfig.DeadTime = 0;
  sBreakDeadTimeConfig.BreakState = TIM_BREAK_DISABLE;
  sBreakDeadTimeConfig.BreakPolarity = TIM_BREAKPOLARITY_HIGH;
  sBreakDeadTimeConfig.AutomaticOutput = TIM_AUTOMATICOUTPUT_DISABLE;
  if (HAL_TIMEx_ConfigBreakDeadTime(&htim1, &sBreakDeadTimeConfig) != HAL_OK)
  {
    Error_Handler();
  }
  HAL_TIM_MspPostInit(&htim1);
}

static void MX_TIM2_Init(void)
{

  TIM_MasterConfigTypeDef sMasterConfig = {0};
  TIM_OC_InitTypeDef sConfigOC = {0};

  htim2.Instance = TIM2;
  htim2.Init.Prescaler = 0;
  htim2.Init.CounterMode = TIM_COUNTERMODE_UP;
  htim2.Init.Period = 0;
  htim2.Init.ClockDivision = TIM_CLOCKDIVISION_DIV1;
  htim2.Init.AutoReloadPreload = TIM_AUTORELOAD_PRELOAD_DISABLE;
  if (HAL_TIM_PWM_Init(&htim2) != HAL_OK)
  {
    Error_Handler();
  }
  sMasterConfig.MasterOutputTrigger = TIM_TRGO_RESET;
  sMasterConfig.MasterSlaveMode = TIM_MASTERSLAVEMODE_DISABLE;
  if (HAL_TIMEx_MasterConfigSynchronization(&htim2, &sMasterConfig) != HAL_OK)
  {
    Error_Handler();
  }
  sConfigOC.OCMode = TIM_OCMODE_PWM1;
  sConfigOC.Pulse = 0;
  sConfigOC.OCPolarity = TIM_OCPOLARITY_HIGH;
  sConfigOC.OCFastMode = TIM_OCFAST_DISABLE;
  if (HAL_TIM_PWM_ConfigChannel(&htim2, &sConfigOC, TIM_CHANNEL_1) != HAL_OK)
  {
    Error_Handler();
  }
  if (HAL_TIM_PWM_ConfigChannel(&htim2, &sConfigOC, TIM_CHANNEL_2) != HAL_OK)
  {
    Error_Handler();
  }
  if (HAL_TIM_PWM_ConfigChannel(&htim2, &sConfigOC, TIM_CHANNEL_3) != HAL_OK)
  {
    Error_Handler();
  }
  if (HAL_TIM_PWM_ConfigChannel(&htim2, &sConfigOC, TIM_CHANNEL_4) != HAL_OK)
  {
    Error_Handler();
  }
  HAL_TIM_MspPostInit(&htim2);
}

static void MX_TIM3_Init(void)
{

  TIM_MasterConfigTypeDef sMasterConfig = {0};
  TIM_OC_InitTypeDef sConfigOC = {0};

  htim3.Instance = TIM3;
  htim3.Init.Prescaler = 0;
  htim3.Init.CounterMode = TIM_COUNTERMODE_UP;
  htim3.Init.Period = 0;
  htim3.Init.ClockDivision = TIM_CLOCKDIVISION_DIV1;
  htim3.Init.AutoReloadPreload = TIM_AUTORELOAD_PRELOAD_DISABLE;
  if (HAL_TIM_PWM_Init(&htim3) != HAL_OK)
  {
    Error_Handler();
  }
  sMasterConfig.MasterOutputTrigger = TIM_TRGO_RESET;
  sMasterConfig.MasterSlaveMode = TIM_MASTERSLAVEMODE_DISABLE;
  if (HAL_TIMEx_MasterConfigSynchronization(&htim3, &sMasterConfig) != HAL_OK)
  {
    Error_Handler();
  }
  sConfigOC.OCMode = TIM_OCMODE_PWM1;
  sConfigOC.Pulse = 0;
  sConfigOC.OCPolarity = TIM_OCPOLARITY_HIGH;
  sConfigOC.OCFastMode = TIM_OCFAST_DISABLE;
  if (HAL_TIM_PWM_ConfigChannel(&htim3, &sConfigOC, TIM_CHANNEL_2) != HAL_OK)
  {
    Error_Handler();
  }
  HAL_TIM_MspPostInit(&htim3);
}

static void MX_TIM4_Init(void)
{

  TIM_MasterConfigTypeDef sMasterConfig = {0};
  TIM_OC_InitTypeDef sConfigOC = {0};

  htim4.Instance = TIM4;
  htim4.Init.Prescaler = 0;
  htim4.Init.CounterMode = TIM_COUNTERMODE_UP;
  htim4.Init.Period = 0;
  htim4.Init.ClockDivision = TIM_CLOCKDIVISION_DIV1;
  htim4.Init.AutoReloadPreload = TIM_AUTORELOAD_PRELOAD_DISABLE;
  if (HAL_TIM_PWM_Init(&htim4) != HAL_OK)
  {
    Error_Handler();
  }
  sMasterConfig.MasterOutputTrigger = TIM_TRGO_RESET;
  sMasterConfig.MasterSlaveMode = TIM_MASTERSLAVEMODE_DISABLE;
  if (HAL_TIMEx_MasterConfigSynchronization(&htim4, &sMasterConfig) != HAL_OK)
  {
    Error_Handler();
  }
  sConfigOC.OCMode = TIM_OCMODE_PWM1;
  sConfigOC.Pulse = 0;
  sConfigOC.OCPolarity = TIM_OCPOLARITY_HIGH;
  sConfigOC.OCFastMode = TIM_OCFAST_DISABLE;
  if (HAL_TIM_PWM_ConfigChannel(&htim4, &sConfigOC, TIM_CHANNEL_1) != HAL_OK)
  {
    Error_Handler();
  }
  if (HAL_TIM_PWM_ConfigChannel(&htim4, &sConfigOC, TIM_CHANNEL_2) != HAL_OK)
  {
    Error_Handler();
  }
  if (HAL_TIM_PWM_ConfigChannel(&htim4, &sConfigOC, TIM_CHANNEL_3) != HAL_OK)
  {
    Error_Handler();
  }
  if (HAL_TIM_PWM_ConfigChannel(&htim4, &sConfigOC, TIM_CHANNEL_4) != HAL_OK)
  {
    Error_Handler();
  }
  HAL_TIM_MspPostInit(&htim4);
}

static void MX_TIM5_Init(void)
{

  TIM_MasterConfigTypeDef sMasterConfig = {0};
  TIM_OC_InitTypeDef sConfigOC = {0};

  htim5.Instance = TIM5;
  htim5.Init.Prescaler = 0;
  htim5.Init.CounterMode = TIM_COUNTERMODE_UP;
  htim5.Init.Period = 0;
  htim5.Init.ClockDivision = TIM_CLOCKDIVISION_DIV1;
  htim5.Init.AutoReloadPreload = TIM_AUTORELOAD_PRELOAD_DISABLE;
  if (HAL_TIM_PWM_Init(&htim5) != HAL_OK)
  {
    Error_Handler();
  }
  sMasterConfig.MasterOutputTrigger = TIM_TRGO_RESET;
  sMasterConfig.MasterSlaveMode = TIM_MASTERSLAVEMODE_DISABLE;
  if (HAL_TIMEx_MasterConfigSynchronization(&htim5, &sMasterConfig) != HAL_OK)
  {
    Error_Handler();
  }
  sConfigOC.OCMode = TIM_OCMODE_PWM1;
  sConfigOC.Pulse = 0;
  sConfigOC.OCPolarity = TIM_OCPOLARITY_HIGH;
  sConfigOC.OCFastMode = TIM_OCFAST_DISABLE;
  if (HAL_TIM_PWM_ConfigChannel(&htim5, &sConfigOC, TIM_CHANNEL_1) != HAL_OK)
  {
    Error_Handler();
  }
  if (HAL_TIM_PWM_ConfigChannel(&htim5, &sConfigOC, TIM_CHANNEL_2) != HAL_OK)
  {
    Error_Handler();
  }
  if (HAL_TIM_PWM_ConfigChannel(&htim5, &sConfigOC, TIM_CHANNEL_3) != HAL_OK)
  {
    Error_Handler();
  }
  if (HAL_TIM_PWM_ConfigChannel(&htim5, &sConfigOC, TIM_CHANNEL_4) != HAL_OK)
  {
    Error_Handler();
  }
  HAL_TIM_MspPostInit(&htim5);
}

static void MX_TIM8_Init(void)
{

  TIM_MasterConfigTypeDef sMasterConfig = {0};
  TIM_OC_InitTypeDef sConfigOC = {0};
  TIM_BreakDeadTimeConfigTypeDef sBreakDeadTimeConfig = {0};

  htim8.Instance = TIM8;
  htim8.Init.Prescaler = 0;
  htim8.Init.CounterMode = TIM_COUNTERMODE_UP;
  htim8.Init.Period = 0;
  htim8.Init.ClockDivision = TIM_CLOCKDIVISION_DIV1;
  htim8.Init.RepetitionCounter = 0;
  htim8.Init.AutoReloadPreload = TIM_AUTORELOAD_PRELOAD_DISABLE;
  if (HAL_TIM_PWM_Init(&htim8) != HAL_OK)
  {
    Error_Handler();
  }
  sMasterConfig.MasterOutputTrigger = TIM_TRGO_RESET;
  sMasterConfig.MasterSlaveMode = TIM_MASTERSLAVEMODE_DISABLE;
  if (HAL_TIMEx_MasterConfigSynchronization(&htim8, &sMasterConfig) != HAL_OK)
  {
    Error_Handler();
  }
  sConfigOC.OCMode = TIM_OCMODE_PWM1;
  sConfigOC.Pulse = 0;
  sConfigOC.OCPolarity = TIM_OCPOLARITY_HIGH;
  sConfigOC.OCNPolarity = TIM_OCNPOLARITY_HIGH;
  sConfigOC.OCFastMode = TIM_OCFAST_DISABLE;
  sConfigOC.OCIdleState = TIM_OCIDLESTATE_RESET;
  sConfigOC.OCNIdleState = TIM_OCNIDLESTATE_RESET;
  if (HAL_TIM_PWM_ConfigChannel(&htim8, &sConfigOC, TIM_CHANNEL_1) != HAL_OK)
  {
    Error_Handler();
  }
  if (HAL_TIM_PWM_ConfigChannel(&htim8, &sConfigOC, TIM_CHANNEL_2) != HAL_OK)
  {
    Error_Handler();
  }
  if (HAL_TIM_PWM_ConfigChannel(&htim8, &sConfigOC, TIM_CHANNEL_3) != HAL_OK)
  {
    Error_Handler();
  }
  if (HAL_TIM_PWM_ConfigChannel(&htim8, &sConfigOC, TIM_CHANNEL_4) != HAL_OK)
  {
    Error_Handler();
  }
  sBreakDeadTimeConfig.OffStateRunMode = TIM_OSSR_DISABLE;
  sBreakDeadTimeConfig.OffStateIDLEMode = TIM_OSSI_DISABLE;
  sBreakDeadTimeConfig.LockLevel = TIM_LOCKLEVEL_OFF;
  sBreakDeadTimeConfig.DeadTime = 0;
  sBreakDeadTimeConfig.BreakState = TIM_BREAK_DISABLE;
  sBreakDeadTimeConfig.BreakPolarity = TIM_BREAKPOLARITY_HIGH;
  sBreakDeadTimeConfig.AutomaticOutput = TIM_AUTOMATICOUTPUT_DISABLE;
  if (HAL_TIMEx_ConfigBreakDeadTime(&htim8, &sBreakDeadTimeConfig) != HAL_OK)
  {
    Error_Handler();
  }
  HAL_TIM_MspPostInit(&htim8);
}

static void MX_TIM12_Init(void)
{

  TIM_OC_InitTypeDef sConfigOC = {0};

  htim12.Instance = TIM12;
  htim12.Init.Prescaler = 0;
  htim12.Init.CounterMode = TIM_COUNTERMODE_UP;
  htim12.Init.Period = 0;
  htim12.Init.ClockDivision = TIM_CLOCKDIVISION_DIV1;
  htim12.Init.AutoReloadPreload = TIM_AUTORELOAD_PRELOAD_DISABLE;
  if (HAL_TIM_OC_Init(&htim12) != HAL_OK)
  {
    Error_Handler();
  }
  sConfigOC.OCMode = TIM_OCMODE_TIMING;
  sConfigOC.Pulse = 0;
  sConfigOC.OCPolarity = TIM_OCPOLARITY_HIGH;
  sConfigOC.OCFastMode = TIM_OCFAST_DISABLE;
  if (HAL_TIM_OC_ConfigChannel(&htim12, &sConfigOC, TIM_CHANNEL_1) != HAL_OK)
  {
    Error_Handler();
  }
  HAL_TIM_MspPostInit(&htim12);
}

static void MX_UART7_Init(void)
{

  huart7.Instance = UART7;
  huart7.Init.BaudRate = 115200;
  huart7.Init.WordLength = UART_WORDLENGTH_8B;
  huart7.Init.StopBits = UART_STOPBITS_1;
  huart7.Init.Parity = UART_PARITY_NONE;
  huart7.Init.Mode = UART_MODE_TX_RX;
  huart7.Init.HwFlowCtl = UART_HWCONTROL_NONE;
  huart7.Init.OverSampling = UART_OVERSAMPLING_16;
  if (HAL_UART_Init(&huart7) != HAL_OK)
  {
    Error_Handler();
  }
}

static void MX_UART8_Init(void)
{

  huart8.Instance = UART8;
  huart8.Init.BaudRate = 115200;
  huart8.Init.WordLength = UART_WORDLENGTH_8B;
  huart8.Init.StopBits = UART_STOPBITS_1;
  huart8.Init.Parity = UART_PARITY_NONE;
  huart8.Init.Mode = UART_MODE_TX_RX;
  huart8.Init.HwFlowCtl = UART_HWCONTROL_NONE;
  huart8.Init.OverSampling = UART_OVERSAMPLING_16;
  if (HAL_UART_Init(&huart8) != HAL_OK)
  {
    Error_Handler();
  }
}

static void MX_USART1_UART_Init(void)
{

  huart1.Instance = USART1;
  huart1.Init.BaudRate = 115200;
  huart1.Init.WordLength = UART_WORDLENGTH_8B;
  huart1.Init.StopBits = UART_STOPBITS_1;
  huart1.Init.Parity = UART_PARITY_NONE;
  huart1.Init.Mode = UART_MODE_TX_RX;
  huart1.Init.HwFlowCtl = UART_HWCONTROL_NONE;
  huart1.Init.OverSampling = UART_OVERSAMPLING_16;
  if (HAL_UART_Init(&huart1) != HAL_OK)
  {
    Error_Handler();
  }
}

static void MX_USART2_UART_Init(void)
{

  huart2.Instance = USART2;
  huart2.Init.BaudRate = 115200;
  huart2.Init.WordLength = UART_WORDLENGTH_8B;
  huart2.Init.StopBits = UART_STOPBITS_1;
  huart2.Init.Parity = UART_PARITY_NONE;
  huart2.Init.Mode = UART_MODE_TX_RX;
  huart2.Init.HwFlowCtl = UART_HWCONTROL_NONE;
  huart2.Init.OverSampling = UART_OVERSAMPLING_16;
  if (HAL_UART_Init(&huart2) != HAL_OK)
  {
    Error_Handler();
  }
}

static void MX_USART3_UART_Init(void)
{

  huart3.Instance = USART3;
  huart3.Init.BaudRate = 115200;
  huart3.Init.WordLength = UART_WORDLENGTH_8B;
  huart3.Init.StopBits = UART_STOPBITS_1;
  huart3.Init.Parity = UART_PARITY_NONE;
  huart3.Init.Mode = UART_MODE_TX_RX;
  huart3.Init.HwFlowCtl = UART_HWCONTROL_NONE;
  huart3.Init.OverSampling = UART_OVERSAMPLING_16;
  if (HAL_UART_Init(&huart3) != HAL_OK)
  {
    Error_Handler();
  }
}

static void MX_USART6_UART_Init(void)
{

  huart6.Instance = USART6;
  huart6.Init.BaudRate = 115200;
  huart6.Init.WordLength = UART_WORDLENGTH_8B;
  huart6.Init.StopBits = UART_STOPBITS_1;
  huart6.Init.Parity = UART_PARITY_NONE;
  huart6.Init.Mode = UART_MODE_TX_RX;
  huart6.Init.HwFlowCtl = UART_HWCONTROL_NONE;
  huart6.Init.OverSampling = UART_OVERSAMPLING_16;
  if (HAL_UART_Init(&huart6) != HAL_OK)
  {
    Error_Handler();
  }
}

static void MX_USB_OTG_FS_USB_Init(void)
{

}

static void MX_GPIO_Init(void)
{
  GPIO_InitTypeDef GPIO_InitStruct = {0};

  /* GPIO Ports Clock Enable */
  __HAL_RCC_GPIOE_CLK_ENABLE();
  __HAL_RCC_GPIOB_CLK_ENABLE();
  __HAL_RCC_GPIOG_CLK_ENABLE();
  __HAL_RCC_GPIOD_CLK_ENABLE();
  __HAL_RCC_GPIOC_CLK_ENABLE();
  __HAL_RCC_GPIOA_CLK_ENABLE();
  __HAL_RCC_GPIOI_CLK_ENABLE();
  __HAL_RCC_GPIOH_CLK_ENABLE();
  __HAL_RCC_GPIOF_CLK_ENABLE();

  /*Configure GPIO pin Output Level */
  HAL_GPIO_WritePin(GPIOE, IST8310_RSTN_Pin | LED_RED_Pin, GPIO_PIN_RESET);

  /*Configure GPIO pin Output Level */
  HAL_GPIO_WritePin(GPIOG, LASER_Pin | LED_A_Pin | LED_B_Pin | LED_C_Pin | LED_D_Pin | LED_E_Pin | LED_F_Pin | LED_G_Pin | LED_H_Pin, GPIO_PIN_RESET);

  /*Configure GPIO pin Output Level */
  HAL_GPIO_WritePin(GPIOH, POWER1_CTRL_Pin | POWER2_CTRL_Pin | POWER3_CTRL_Pin | POWER4_CTRL_Pin, GPIO_PIN_RESET);

  /*Configure GPIO pin Output Level */
  HAL_GPIO_WritePin(GPIOF, GPIO_PIN_10 | LED_GREEN_Pin, GPIO_PIN_RESET);

  /*Configure GPIO pins : IST8310_DRDY_Pin SD_EXTI_Pin */
  GPIO_InitStruct.Pin = IST8310_DRDY_Pin | SD_EXTI_Pin;
  GPIO_InitStruct.Mode = GPIO_MODE_IT_RISING;
  GPIO_InitStruct.Pull = GPIO_NOPULL;
  HAL_GPIO_Init(GPIOE, &GPIO_InitStruct);

  /*Configure GPIO pins : IST8310_RSTN_Pin LED_RED_Pin */
  GPIO_InitStruct.Pin = IST8310_RSTN_Pin | LED_RED_Pin;
  GPIO_InitStruct.Mode = GPIO_MODE_OUTPUT_PP;
  GPIO_InitStruct.Pull = GPIO_NOPULL;
  GPIO_InitStruct.Speed = GPIO_SPEED_FREQ_LOW;
  HAL_GPIO_Init(GPIOE, &GPIO_InitStruct);

  /*Configure GPIO pins : IMU_INT_Pin KEY_Pin */
  GPIO_InitStruct.Pin = IMU_INT_Pin | KEY_Pin;
  GPIO_InitStruct.Mode = GPIO_MODE_IT_RISING;
  GPIO_InitStruct.Pull = GPIO_NOPULL;
  HAL_GPIO_Init(GPIOB, &GPIO_InitStruct);

  /*Configure GPIO pins : LASER_Pin LED_A_Pin LED_B_Pin LED_C_Pin
                           LED_D_Pin LED_E_Pin LED_F_Pin LED_G_Pin
                           LED_H_Pin */
  GPIO_InitStruct.Pin = LASER_Pin | LED_A_Pin | LED_B_Pin | LED_C_Pin | LED_D_Pin | LED_E_Pin | LED_F_Pin | LED_G_Pin | LED_H_Pin;
  GPIO_InitStruct.Mode = GPIO_MODE_OUTPUT_PP;
  GPIO_InitStruct.Pull = GPIO_NOPULL;
  GPIO_InitStruct.Speed = GPIO_SPEED_FREQ_LOW;
  HAL_GPIO_Init(GPIOG, &GPIO_InitStruct);

  /*Configure GPIO pins : PD7 PD4 PD3 PD11
                           PD10 */
  GPIO_InitStruct.Pin = GPIO_PIN_7 | GPIO_PIN_4 | GPIO_PIN_3 | GPIO_PIN_11 | GPIO_PIN_10;
  GPIO_InitStruct.Mode = GPIO_MODE_ANALOG;
  GPIO_InitStruct.Pull = GPIO_NOPULL;
  HAL_GPIO_Init(GPIOD, &GPIO_InitStruct);

  /*Configure GPIO pin : PA15 */
  GPIO_InitStruct.Pin = GPIO_PIN_15;
  GPIO_InitStruct.Mode = GPIO_MODE_ANALOG;
  GPIO_InitStruct.Pull = GPIO_NOPULL;
  HAL_GPIO_Init(GPIOA, &GPIO_InitStruct);

  /*Configure GPIO pins : PB9 PB10 PB11 PB14
                           PB15 */
  GPIO_InitStruct.Pin = GPIO_PIN_9 | GPIO_PIN_10 | GPIO_PIN_11 | GPIO_PIN_14 | GPIO_PIN_15;
  GPIO_InitStruct.Mode = GPIO_MODE_ANALOG;
  GPIO_InitStruct.Pull = GPIO_NOPULL;
  HAL_GPIO_Init(GPIOB, &GPIO_InitStruct);

  /*Configure GPIO pins : PG15 PG12 PG11 PG10
                           PG0 */
  GPIO_InitStruct.Pin = GPIO_PIN_15 | GPIO_PIN_12 | GPIO_PIN_11 | GPIO_PIN_10 | GPIO_PIN_0;
  GPIO_InitStruct.Mode = GPIO_MODE_ANALOG;
  GPIO_InitStruct.Pull = GPIO_NOPULL;
  HAL_GPIO_Init(GPIOG, &GPIO_InitStruct);

  /*Configure GPIO pins : PA12 PA11 PA10 */
  GPIO_InitStruct.Pin = GPIO_PIN_12 | GPIO_PIN_11 | GPIO_PIN_10;
  GPIO_InitStruct.Mode = GPIO_MODE_AF_PP;
  GPIO_InitStruct.Pull = GPIO_NOPULL;
  GPIO_InitStruct.Speed = GPIO_SPEED_FREQ_VERY_HIGH;
  GPIO_InitStruct.Alternate = GPIO_AF10_OTG_FS;
  HAL_GPIO_Init(GPIOA, &GPIO_InitStruct);

  /*Configure GPIO pins : PI3 PI8 PI4 PI1
                           PI10 PI11 */
  GPIO_InitStruct.Pin = GPIO_PIN_3 | GPIO_PIN_8 | GPIO_PIN_4 | GPIO_PIN_1 | GPIO_PIN_10 | GPIO_PIN_11;
  GPIO_InitStruct.Mode = GPIO_MODE_ANALOG;
  GPIO_InitStruct.Pull = GPIO_NOPULL;
  HAL_GPIO_Init(GPIOI, &GPIO_InitStruct);

  /*Configure GPIO pins : PC13 PC14 PC15 PC7
                           PC6 */
  GPIO_InitStruct.Pin = GPIO_PIN_13 | GPIO_PIN_14 | GPIO_PIN_15 | GPIO_PIN_7 | GPIO_PIN_6;
  GPIO_InitStruct.Mode = GPIO_MODE_ANALOG;
  GPIO_InitStruct.Pull = GPIO_NOPULL;
  HAL_GPIO_Init(GPIOC, &GPIO_InitStruct);

  /*Configure GPIO pin : PI9 */
  GPIO_InitStruct.Pin = GPIO_PIN_9;
  GPIO_InitStruct.Mode = GPIO_MODE_IT_RISING;
  GPIO_InitStruct.Pull = GPIO_NOPULL;
  HAL_GPIO_Init(GPIOI, &GPIO_InitStruct);

  /*Configure GPIO pins : PH15 PH13 PH14 PH8
                           PH9 PH7 */
  GPIO_InitStruct.Pin = GPIO_PIN_15 | GPIO_PIN_13 | GPIO_PIN_14 | GPIO_PIN_8 | GPIO_PIN_9 | GPIO_PIN_7;
  GPIO_InitStruct.Mode = GPIO_MODE_ANALOG;
  GPIO_InitStruct.Pull = GPIO_NOPULL;
  HAL_GPIO_Init(GPIOH, &GPIO_InitStruct);

  /*Configure GPIO pins : POWER1_CTRL_Pin POWER2_CTRL_Pin POWER3_CTRL_Pin POWER4_CTRL_Pin */
  GPIO_InitStruct.Pin = POWER1_CTRL_Pin | POWER2_CTRL_Pin | POWER3_CTRL_Pin | POWER4_CTRL_Pin;
  GPIO_InitStruct.Mode = GPIO_MODE_OUTPUT_PP;
  GPIO_InitStruct.Pull = GPIO_NOPULL;
  GPIO_InitStruct.Speed = GPIO_SPEED_FREQ_LOW;
  HAL_GPIO_Init(GPIOH, &GPIO_InitStruct);

  /*Configure GPIO pins : PF2 PF3 PF13 PF12
                           PF15 PF11 */
  GPIO_InitStruct.Pin = GPIO_PIN_2 | GPIO_PIN_3 | GPIO_PIN_13 | GPIO_PIN_12 | GPIO_PIN_15 | GPIO_PIN_11;
  GPIO_InitStruct.Mode = GPIO_MODE_ANALOG;
  GPIO_InitStruct.Pull = GPIO_NOPULL;
  HAL_GPIO_Init(GPIOF, &GPIO_InitStruct);

  /*Configure GPIO pins : PF10 LED_GREEN_Pin */
  GPIO_InitStruct.Pin = GPIO_PIN_10 | LED_GREEN_Pin;
  GPIO_InitStruct.Mode = GPIO_MODE_OUTPUT_PP;
  GPIO_InitStruct.Pull = GPIO_NOPULL;
  GPIO_InitStruct.Speed = GPIO_SPEED_FREQ_LOW;
  HAL_GPIO_Init(GPIOF, &GPIO_InitStruct);

  /*Configure GPIO pins : PE9 PE10 */
  GPIO_InitStruct.Pin = GPIO_PIN_9 | GPIO_PIN_10;
  GPIO_InitStruct.Mode = GPIO_MODE_ANALOG;
  GPIO_InitStruct.Pull = GPIO_NOPULL;
  HAL_GPIO_Init(GPIOE, &GPIO_InitStruct);
}

void StartDefaultTask(void const *argument)
{

  /* USER CODE BEGIN 5 */
  static uint8_t txbuf[2] = {0x0A};
  /* Infinite loop */
  for (;;)
  {
    HAL_I2C_Master_Transmit_DMA(&hi2c2, 0x79, txbuf, 1);
    HAL_GPIO_TogglePin(LED_GREEN_GPIO_Port, LED_GREEN_Pin);
    osDelay(100);
  }
  /* USER CODE END 5 */
}

void HAL_TIM_PeriodElapsedCallback(TIM_HandleTypeDef *htim)
{
  if (htim->Instance == TIM14)
  {
    HAL_IncTick();
  }
}

void Error_Handler(void)
{
}

/************************ (C) COPYRIGHT STMicroelectronics *****END OF FILE****/
